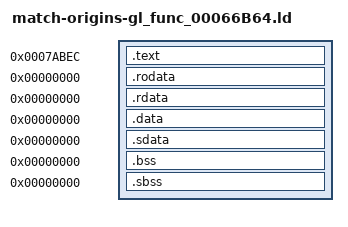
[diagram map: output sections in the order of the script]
/* Standard linker bindings; original USO identity is independently audited. */
SECTIONS {
 .text 0x7abec : SUBALIGN(4) { *(.text) *(.text.*) }
 .rodata 0x0 : SUBALIGN(4) { *(.rodata) *(.rodata.*) }
 .rdata 0x0 : SUBALIGN(4) { *(.rdata) *(.rdata.*) }
 .data 0x0 : SUBALIGN(4) { *(.data) *(.data.*) }
 .sdata 0x0 : SUBALIGN(4) { *(.sdata) *(.sdata.*) }
 .bss 0x0 : SUBALIGN(4) { *(.bss) *(.bss.*) }
 .sbss 0x0 : SUBALIGN(4) { *(.sbss) *(.sbss.*) }
 /DISCARD/ : { *(.mdebug) *(.reginfo) *(.pdr) *(.comment) *(.MIPS.abiflags) *(.options) }
}
gl_import_66B64_osCreateThread = 0x0;
gl_import_66B64_osInitialize = 0x0;
gl_import_66B64_osStartThread = 0x0;
gl_import_66B64_threadEntry = 0x0;
